# SF32LB58x register map
File version: 1.0
CPU: CM33 r0p1, little endian, MPU, FPU, 3 interrupt priority bits
Registers are 32-bit, read-write, reset 0x0 unless marked. A register's access mark holds for its fields unless they carry their own. Offsets are from the block's base; [hi:lo] are bit positions; {n}, {i} and the like mark numbered series.

## JPEG_DEC
Base 0x4008A000
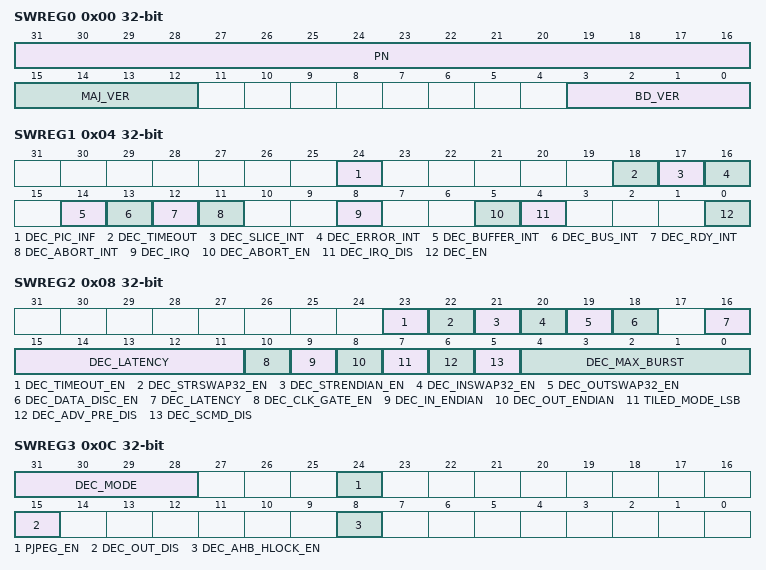
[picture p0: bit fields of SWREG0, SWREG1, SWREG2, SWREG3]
0x00 SWREG0
  [31:16] PN — Product number
  [15:12] MAJ_VER — Major version
  [3:0] BD_VER — Build version(core number)
0x04 SWREG1
  [24] DEC_PIC_INF — B slice detected. This signal is driven high during picture ready interrupt if B-type slice is found. This bit does not generate an interrupt but is used to inform SW about h264 tools. DIVX3: For DIVX3 this bit tells the value of extension header flag (flag called FLIPFLOP)
  [18] DEC_TIMEOUT — Interrupt status bit decoder timeout. When high the decoder has been idling for too long. HW will self reset. Possible only if timeout interrupt is enabled.
  [17] DEC_SLICE_INT — Interrupt status bit dec_slice_decoded . When high SW must set new base addresses for sw_dec_out_base and sw_jpg_ch_out_base before resetting this status bit. Used for JPEG and VP8 web-p modes.
  [16] DEC_ERROR_INT — Interrupt status bit input stream error . When high, an error is found in input data stream decoding. HW will self reset.
  [14] DEC_BUFFER_INT — Interrupt status bit input buffer empty. When high, input stream buffer is empty but picture is not ready. HW will not self reset.
  [13] DEC_BUS_INT — Interrupt status bit bus. Error response from bus.
  [12] DEC_RDY_INT — Interrupt status bit decoder. When this bit is high decoder has decoded a picture. HW will self reset.
  [11] DEC_ABORT_INT — Interrupt status bit decoding aborted. When this bit is high decoder has aborted the current picture decoding as SW requested (sw_dec_abort_e). Decoder self reset and sw_dec_abort_e written low.
  [8] DEC_IRQ — Decoder IRQ. When high, decoder requests an interrupt. SW will reset this after interrupt is handled.
  [5] DEC_ABORT_EN — Abort decoding enable. Setting this bit high will cause HW to abort decoding and safely to reset itself down. After abort is complete the corresponding interrupt status is set and this bit is set low as well as the decoder enable.
  [4] DEC_IRQ_DIS — Decoder IRQ disable. When high, there are no interrupts concerning decoder from HW. Polling must be used to see the interrupt statuses.
  [0] DEC_EN — Decoder enable. Setting this bit high will start the decoding operation. HW will reset this when picture is processed or ASO or stream error is detected or bus error or timeout interrupt is given.
0x08 SWREG2
  [23] DEC_TIMEOUT_EN — Timeout interrupt enable. If enabled HW may return timeout interrupt in case HW gets stucked while decoding picture.
  [22] DEC_STRSWAP32_EN — Decoder input 32bit data swap for stream data (may be used for 64 bit environment): ‘0’ = no swapping of 32 bit words ‘1’ = 32 bit data words are swapped (needed in 64 bit environment to achieve 7-6-5-4-3-2-1-0 byte order(also little endian should be enabled)
  [21] DEC_STRENDIAN_EN — Decoder input endian mode for stream data: 0 = Big endian (0-1-2-3 order) 1 = Little endian (3-2-1-0 order)
  [20] DEC_INSWAP32_EN — Decoder input 32 bit data swap for other than stream data (may be used for 64 bit environment): ‘0’ = no swapping of 32 bit words ‘1’ = 32 bit data words are swapped (needed in 64 bit environment to achieve 7-6-5-4-3-2-1-0 byte order(also little endian should be enabled).
  [19] DEC_OUTSWAP32_EN — Decoder output 32 bit data swap (may be used for 64 bit environment): ‘0’ = no swapping of 32 bit words ‘1’ = 32 bit data words are swapped (needed in 64 bit environment to achieve 7-6-5-4-3-2-1-0 byte order(also little endian should be enabled).
  [18] DEC_DATA_DISC_EN — Data discard enable. Precise burst lengths are used with reading services. Extra data is discarded internally. Note. If AHB maxburst 17 is used data discard cannot be enabled (causes conflict).
  [16:11] DEC_LATENCY
  [10] DEC_CLK_GATE_EN — Decoder dynamic clock gating enable: 0 = Clock is running for all structures 1 = Clock is gated for decoder structures that are not used Note: Clock gating value can be changed only when decoder is disabled
  [9] DEC_IN_ENDIAN — Decoder input endian mode for other than stream data: 0 = Big endian (0-1-2-3 order) 1 = Little endian (3-2-1-0 order)
  [8] DEC_OUT_ENDIAN — Decoder output endian mode: 0 = Big endian (0-1-2-3 order) 1 = Little endian (3-2-1-0 order)
  [7] TILED_MODE_LSB — Tiled mode LSB. Concatenated to Tiled mode MSB which form 2 bit tiled mode. Defined in tiled_mode_msb.
  [6] DEC_ADV_PRE_DIS — Advanced PREFETCH mode disable (advanced reference picture reading mode for video)
  [5] DEC_SCMD_DIS — AXI Single Command Multiple Data disable. AXI wrapper supports this mode by default (where only the first addresses of the burst are given from address generator). This bit is used to disable the feature (possible SW workaround if something is not working correctly).
  [4:0] DEC_MAX_BURST — Maximum burst length for decoder bus transactions. Valid values: AHB: 1, 4, 8, 16 and 17. Other values will result in INCR type (undefined length) for all transfers. INCR used for lengths 2 and 3. 17 = fixed bursts are used when possible. INCR bursts are used for lengths 2, 3, 5, 6, 7, 9, 10, 11, 12, 13, 14 and 15. OCP: 16-31 AXI: 1-16
0x0C SWREG3
  [31:28] DEC_MODE — Decoding mode: 0 = H.264, 1 = MPEG-4, 2 = H.263, 3 = JPEG, 4 = VC-1, 5 = MPEG-2, 6 = MPEG-1, 7 = VP6, 8 = RV, 9 = VP7, 10 = VP8, 11 = AVS, others = reserved
  [24] PJPEG_EN — Progressive JPEG enable: '0' = baseline JPEG '1' = progressive JPEG
  [15] DEC_OUT_DIS — Disable decoder output picture writing: 0 = Decoder output picture is written to external memory 1 = Decoder output picture is not written to external memory
  [8] DEC_AHB_HLOCK_EN — AHB master HLOCK enable. When high the service is locked to the decoder as long as it needs the bus (whenever decoder requests the bus it will be granted).
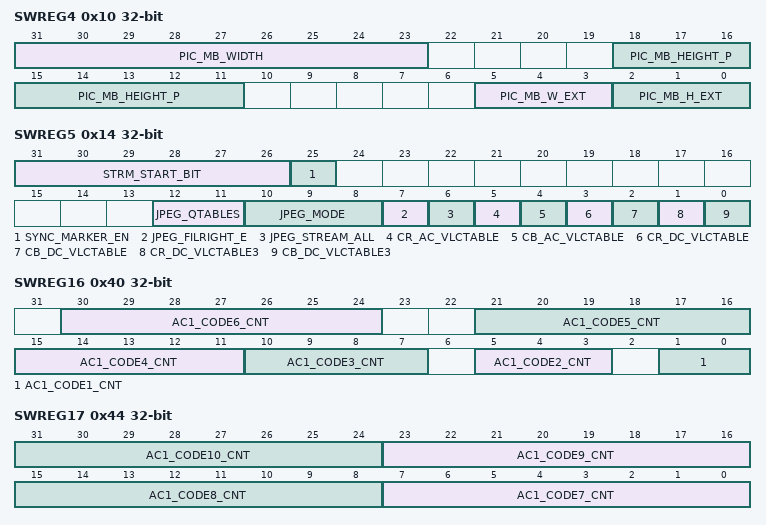
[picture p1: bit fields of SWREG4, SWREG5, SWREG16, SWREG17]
0x10 SWREG4
  [31:23] PIC_MB_WIDTH — Picture width in macroblocks = ((width in pixels + 15) /16)
  [18:11] PIC_MB_HEIGHT_P — Picture height in macroblocks =((height in pixels+15)/16). Picture height is informed as size of the (progressive) frame also for single field (of interlaced content) is being decoded.
  [5:3] PIC_MB_W_EXT — Picture MB width extension. If sw_pic_mb_width does not fit to 9 bits then these bits are used to increase the range up to 11 bits (used as 3 MSB).
  [2:0] PIC_MB_H_EXT — Picture MB height extension. If sw_pic_mb_height_p does not fit to 9 bits then these bits are used to increase the range up to 11 bits (used as 3 MSB). For 4K video, one bit is used for extension (bit 0).
0x14 SWREG5
  [31:26] STRM_START_BIT — Exact bit of stream start word where decoding can be started (associated with sw_rlc_vlc_base).
  [25] SYNC_MARKER_EN — Sync markers enable: '0' = synch markers are not used, '1' = synch markers are used. For progressive JPEG this indicates that there are restart markers in the stream after restart interval steps.
  [12:11] JPEG_QTABLES — Amount of Quantization tables in external memory: 0 = No quantization tables. (not supported) 1 = One quantization table. Used when picture is single type 2 = Two quantization tables. One for luminance and one for chominances. (not supported) 3 = Three quantization tables. Each type (Lu, Cr, Cb) has own QP-table Base address for tables is defined in swreg40.
  [10:8] JPEG_MODE — Input picture sampling format: 0 = single type, MB 1 block, 1 = single type, MB 4 blocks (not supported), 2 = three types, MB 6 blocks (4:2:0), 3 = three types, MB 4 blocks (4:2:2), 4 = three types, MB 3 blocks (4:4:4) 5 = three types, MB 4 blocks (4:4:0) 6 = three types, MB 6 blocks (4:1:1)
  [7] JPEG_FILRIGHT_E — 0 = JPEG picture width is a multiple of 16. 1 = JPEG picture width is a multiple of 8 pixels but not a multiple of 16 pixels. Can be set to 1 only for JPEG sampling format 0. HW must fill one block of zero pixel data to the right border of the picture.
  [6] JPEG_STREAM_ALL — 0 = Current stream buffer does not contain the end of a JPEG image. HW will not flush the stream data pipeline after a buffer empty request. 1 = Current stream buffer contains the end of a JPEG image. HW will flush data pipeline and will not request more stream providing it finds the EOI pattern at the end.
  [5] CR_AC_VLCTABLE — Defines which VLC table should be used for decoding AC components of the Cr. 0 = first, 1 = second. (For luminance the first table is always used)
  [4] CB_AC_VLCTABLE — Defines which VLC table should be used for decoding AC components of the Cb. 0 = first, 1 = second. (For luminance the first table is always used)
  [3] CR_DC_VLCTABLE — Defines which VLC table should be used for decoding DC components of the Cr. 0 = first/third depending on sw_cr_dc_vlctable3 position, 1 = second. (For luminance the first table is always used)
  [2] CB_DC_VLCTABLE — Defines which VLC table should be used for decoding DC components of the Cb. 0 = first/third depending on sw_cr_dc_vlctable3 position, 1 = second. (For luminance the first table is always used)
  [1] CR_DC_VLCTABLE3 — Progressive JPEG: Defines if third VLC table for DC components should be used for Cr. Note: sw_cr_dc_vlctable must be set to '0'
  [0] CB_DC_VLCTABLE3 — Progressive JPEG: Defines if third VLC table for DC components should be used for Cb. Note: sw_cb_dc_vlctable must be set to '0'
0x18 SWREG6
  [23:0] STREAM_LEN — Amount of stream data bytes in input buffer. If the given buffer size is not enough for finishing the picture the corresponding interrupt is given and new stream buffer base address and stream buffer size information should be given (associated with sw_rlc_vlc_base). For VC-1/VP6 the buffer must include data for one picture/slice of the picture. For H264/MPEG4/H263/MPEG2/MPEG1 the buffer must include at least data for one slice/VP of the picture For JPEG the buffer size must be a multiple of 256 bytes or the amount of data for one picture.
0x30 SWREG12
  [31:2] RLC_VLC_BASE — RLC mode: Base address for RLC data (swreg3.sw_rlc_mode_e = 1). VLC mode: Stream start address / end addr+I288ess with byte precision (swreg4.rlc_mode_en = 0), start bit number in swreg5.stream_start_bit. When sw_dec_buffer_int is high or sw_dec_e is low this register contains HW return value of last_byte_address (not valid for jpeg) where stream has been read (and used) in accuracy of byte. For debug purposes the last_byte_address is also written when stream error/ASO is detected even though it may not be accurate. VP7/VP8: This base address is used as sw_dct_strm0_base including DCT stream for MB rows 0,2n
0x34 SWREG13
  [31:2] DEC_OUT_BASE — Video: Base address for decoder output picture. Points directly to start of decoder output picture or field. JPEG/web-p: Base address for decoder output luminance picture
0x38 SWREG14
  [31:2] JPG_CH_OUT_BASE — Base address for decoder output chrominance picture. Used in JPEG and webP picture mode (not needed if decoder output is not written).
0x3C SWREG15
  [7:0] JPEG_SLICE_H — JPEG/Web-p. Height of the slice (multiple of 16 pixels) that HW decodes before interrupt. When slice is decoded HW will generate an interrupt and reset external addresses back to base address. Note, value 0 disables slice mode. Slice mode must be used if picture size is more than 16 Mpixels. However for bigger than 4096 MBs the slice mode usage is recommended.
0x40 SWREG16
  [30:24] AC1_CODE6_CNT — Amount of code words of length 6
  [21:16] AC1_CODE5_CNT — Amount of code words of length 5
  [15:11] AC1_CODE4_CNT — Amount of code words of length 4
  [10:7] AC1_CODE3_CNT — Amount of code words of length 3
  [5:3] AC1_CODE2_CNT — Amount of code words of length 2
  [1:0] AC1_CODE1_CNT — Amount of code words of length 1
0x44 SWREG17
  [8n-49:8n-56] AC1_CODE{n}_CNT (n=7..10) — Amount of code words of length {n}
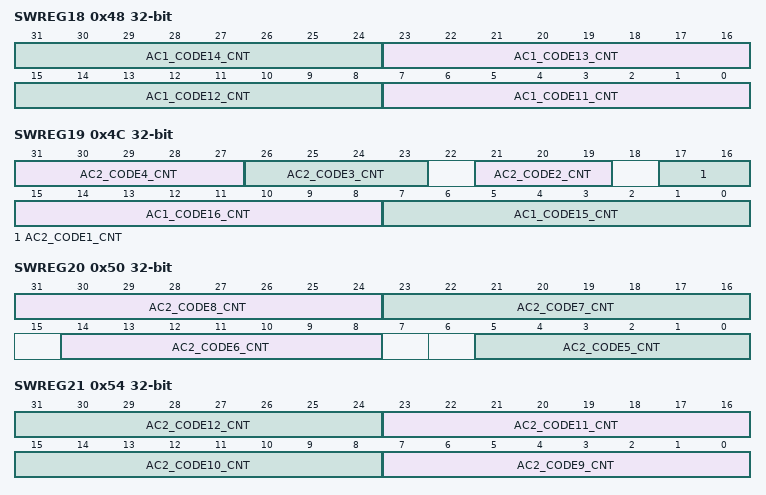
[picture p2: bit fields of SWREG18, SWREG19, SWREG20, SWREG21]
0x48 SWREG18
  [8n-81:8n-88] AC1_CODE{n}_CNT (n=11..14) — Amount of code words of length {n}
0x4C SWREG19
  [31:27] AC2_CODE4_CNT — Amount of code words of length 4 (second table)
  [26:23] AC2_CODE3_CNT — Amount of code words of length 3 (second table)
  [21:19] AC2_CODE2_CNT — Amount of code words of length 2 (second table)
  [17:16] AC2_CODE1_CNT — Amount of code words of length 1 (second table)
  [15:8] AC1_CODE16_CNT — Amount of code words of length 16 (first table)
  [7:0] AC1_CODE15_CNT — Amount of code words of length 15 (first table)
0x50 SWREG20
  [31:24] AC2_CODE8_CNT — Amount of code words of length 8
  [23:16] AC2_CODE7_CNT — Amount of code words of length 7
  [14:8] AC2_CODE6_CNT — Amount of code words of length 6
  [5:0] AC2_CODE5_CNT — Amount of code words of length 5
0x54 SWREG21
  [8n-65:8n-72] AC2_CODE{n}_CNT (n=9..12) — Amount of code words of length {n}
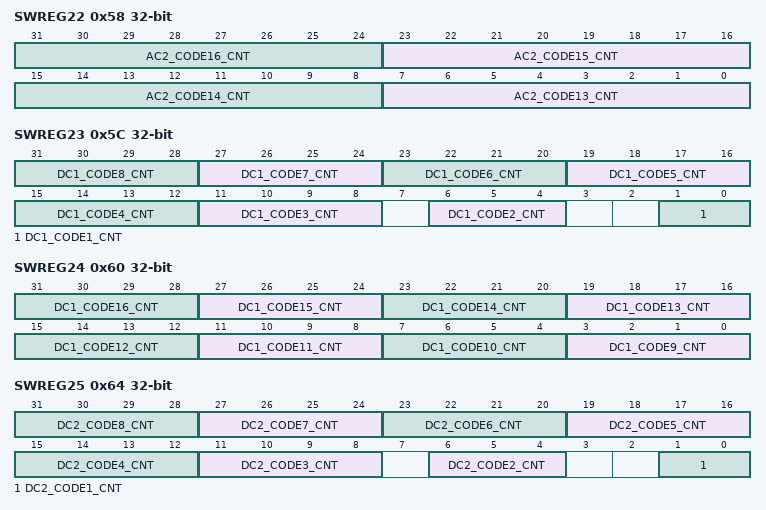
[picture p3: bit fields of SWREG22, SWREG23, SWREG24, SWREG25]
0x58 SWREG22
  [8n-97:8n-104] AC2_CODE{n}_CNT (n=13..16) — Amount of code words of length {n}
0x5C SWREG23
  [4n-1:4n-4] DC1_CODE{n}_CNT (n=3..8) — Amount of code words of length {n}
  [6:4] DC1_CODE2_CNT — Amount of code words of length 2
  [1:0] DC1_CODE1_CNT — Amount of code words of length 1
0x60 SWREG24
  [4n-33:4n-36] DC1_CODE{n}_CNT (n=9..16) — Amount of code words of length {n}
0x64 SWREG25
  [4n-1:4n-4] DC2_CODE{n}_CNT (n=3..8) — Amount of code words of length {n}
  [6:4] DC2_CODE2_CNT — Amount of code words of length 2
  [1:0] DC2_CODE1_CNT — Amount of code words of length 1
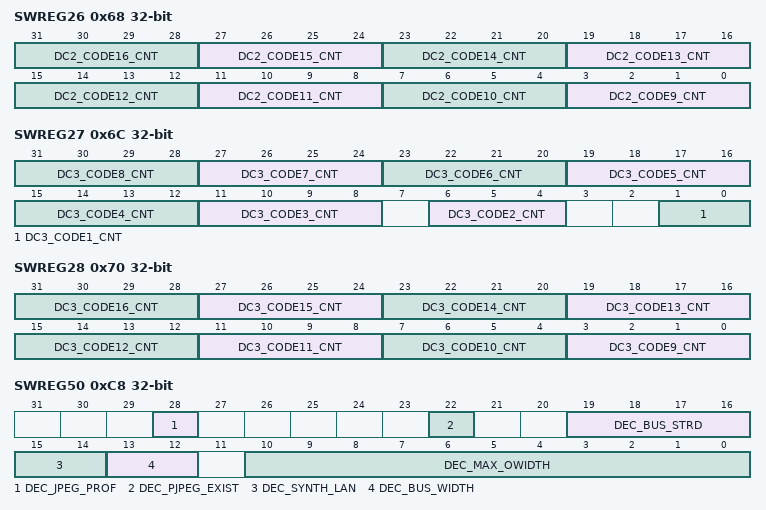
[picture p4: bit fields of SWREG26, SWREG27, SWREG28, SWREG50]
0x68 SWREG26
  [4n-33:4n-36] DC2_CODE{n}_CNT (n=9..16) — Amount of code words of length {n}
0x6C SWREG27
  [4n-1:4n-4] DC3_CODE{n}_CNT (n=3..8) — Amount of code words of length {n}
  [6:4] DC3_CODE2_CNT — Amount of code words of length 2
  [1:0] DC3_CODE1_CNT — Amount of code words of length 1
0x70 SWREG28
  [4n-33:4n-36] DC3_CODE{n}_CNT (n=9..16) — Amount of code words of length {n}
0xA0 SWREG40
  [31:2] QTABLE_BASE — Base address for standard dependent tables: JPEG= AC, DC, QP tables MPEG4=QP table base address if type 1 quantization is used MPEG2=QP table base address H.264=base address for various tables VP6,VP7,VP8=base address for stream decoding tables RV=base address for picture slice sizes
0xA4 SWREG41
  [31:2] DIR_MV_BASE — Direct mode motion vector write/read base address. For H264 this is used only for direct mode motion vector write base. Progressive JPEG: AC/DC coefficient read/write base address. If current round is for DC components this base address is pointing to luminance (separate base adderesses for chrominances), for AC component rounds this base is used for current type VP8: Motion vectors are written for error concealment purposes if sw_write_mvs is high. In error concealment mode motion vectors are read from this base address
0xC8 SWREG50
  [28] DEC_JPEG_PROF — Decoding format support, JPEG 0 = not supported 1 = supported
  [22] DEC_PJPEG_EXIST — Progressive JPEG support: '0' = Not supported '1' = supported
  [19:16] DEC_BUS_STRD — Connected to standard bus: 0 = error 1 = AHB master, AHB slave 2 = OCP master, OCP slave 3 = AXI master, AXI slave 4 = AXI master, APB slave 5 = AXI master, AHB slave
  [15:14] DEC_SYNTH_LAN — 0 = error 1 = VHDL 2 = Verilog
  [13:12] DEC_BUS_WIDTH — 0 = error 1 = 32 bit bus 2 = 64 bit bus 3 = 128 bit bus
  [10:0] DEC_MAX_OWIDTH — Max configured decoder video resolution that can be decoded. Informed as width of the picture in pixels.
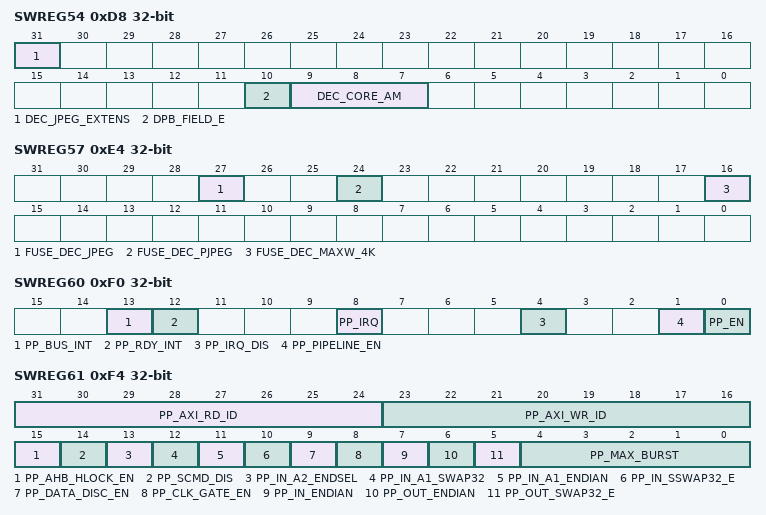
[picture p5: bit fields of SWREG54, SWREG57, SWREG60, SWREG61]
0xD8 SWREG54
  [31] DEC_JPEG_EXTENS — JPEG sampling support extension for 411 and 444 samplings and support for max resolution larger than 16 Mpix (up to 67 Mpixels): '0' = not supported '1' = supported
  [10] DPB_FIELD_E — DPB field separate mode support for ilaced content: '0' = Not supported (for ilaced content DPB is ilaced frame order) '1' = Supported, For ilaced content DPB can consis of ilaced frames or separate fields (TOP/BOT)
  [9:7] DEC_CORE_AM — Decoder core amount. If other than 0 the multicore can be used. Each individual cores can be identified from corresponding core ID register: 0= single core decoder 1= dual core decoder ... 7=8 core decoder
0xE4 SWREG57
  [27] FUSE_DEC_JPEG — 1 = JPEG enabled
  [24] FUSE_DEC_PJPEG — 1 = Progressive JPEG enabled (Requires JPEG to also be enabled)
  [16] FUSE_DEC_MAXW_4K — 1 = Max video width up to 4096 pixels enabled. Priority coded with priority 1.
0xE8 SWREG58
  [31] SERV_MERGE_DIS — Decoder service merge disable: '0': HW merges simultaneous sub-block requests internally if they are same type (read or write) '1': decoder serves one sub-block per service and merging is disabled.
0xF0 SWREG60
  [13] PP_BUS_INT — Interrupt status bit bus. Error response from bus. In pipeline mode this bit is not used.
  [12] PP_RDY_INT — Interrupt status bit post processor. When this bit is high, post processor has processed a picture in external mode. In pipeline mode this bit is not used.
  [8] PP_IRQ — Post-processor IRQ. SW will reset this after interrupt is handled. HINTpp is not used for PP if IRQ disable PP is high (sw_pp_irq_n_e = 1). In pipeline mode this bit is not used
  [4] PP_IRQ_DIS — Post-processor IRQ disabled. When high, there are no interrupts from HW concerning post processing. Polling must be used to see the interrupt
  [1] PP_PIPELINE_EN — Decoder – post-processing pipeline enable: 0 = Post-processing is processing different picture than decoder or is disabled 1 = Post-processing is performed in pipeline with decoder
  [0] PP_EN — External mode post-processing enable. This bit will start the post-processing operation. Not to be used if PP is in pipeline with decoder (sw_pp_pipeline_e = 1). HW will reset this when picture is post-processed.
0xF4 SWREG61
  [31:24] PP_AXI_RD_ID — Read ID used for AXI PP read services (if connected to AXI). If value 255 is given the decoder will provide data type based dynamic index (defined in toplevel_sp).
  [23:16] PP_AXI_WR_ID — Write ID used for AXI PP write services (if connected to AXI). If value 255 is given the decoder will provide data type based dynamic index (defined in toplevel_sp).
  [15] PP_AHB_HLOCK_EN — AHB master HLOCK enable. When high the service is locked to PP as long as it needs the bus (whenever PP requests the bus it will be granted).
  [14] PP_SCMD_DIS — AXI Single Command Multiple Data disable. AXI wrapper supports this mode by default (where only the first addresses of the burst are given from address generator). This bit is used to disable the feature (possible SW workaround if something is not working correctly).
  [13] PP_IN_A2_ENDSEL — Endian/swap select for Alpha blend input source 2: '0' = Use PP in endian/swap definitions (sw_pp_in_endian, sw_pp_in_swap ) '1' = Use Alpha blend source 1 endian/swap definitions (sw_pp_in_a1_endian, sw_pp_in_a1_swap )
  [12] PP_IN_A1_SWAP32 — Alpha blend source 1 input 32 bit data swap (may be used for 64 bit environment): ‘0’ = no swapping of 32 bit words ‘1’ = 32 bit data words are swapped (needed in 64 bit environment to achieve 7-6-5-4-3-2-1-0 byte order (also little endian should be enabled)
  [11] PP_IN_A1_ENDIAN — Alpha blend source 1 input data byte endian mode. 0 = Big endian (0-1-2-3 order) 1 = Little endian (3-2-1-0 order)
  [10] PP_IN_SSWAP32_E — PP input 32 bit data swap (may be used for 64 bit environment): ‘0’ = no swapping of 32 bit words ‘1’ = 32 bit data words are swapped (needed in 64 bit environment to achieve 7-6-5-4-3-2-1-0 byte order (also little endian should be enabled).
  [9] PP_DATA_DISC_EN — PP data discard enable. Precise burst lengths are used with reading services. Extra data is discarded internally. Note. If AHB maxburst 17 is used data discard cannot be enabled (causes conflict).
  [8] PP_CLK_GATE_EN — PP dynamic clock gating enable: 1 = Clock is gated from PP structures that are not used 0 = Clock is running for all PP structures Note: Clock gating value can be changed only when PP is not enabled
  [7] PP_IN_ENDIAN — PP input picture byte endian mode. Used only if PP is in standalone mode. If PP is running pipelined with the decoder, this bit has no effect. 0 = Big endian (0-1-2-3 order) 1 = Little endian (3-2-1-0 order)
  [6] PP_OUT_ENDIAN — PP output picture endian mode for YCbCr data or for any data if config value SW_PP_OEN_VERSION=1 0 = Big endian (0-1-2-3 order) 1 = Little endian (3-2-1-0 order) (NOTE: For SW_PP_OEN_VERSION=0 16 bit RGB data this bit works as pixel swapping bit. For 32 bit RGB this bit has no meaning)
  [5] PP_OUT_SWAP32_E — PP output data word swap (may be used for 64 bit environment): ‘0’ = no swapping of 32 bit words ‘1’ = 32 bit data words are swapped (needed in 64 bit environment to achieve 7-6-5-4-3-2-1-0 byte order (also little endian should be enabled).
  [4:0] PP_MAX_BURST — Maximum burst length for PP bus transactions. Valid values: AHB: 1, 4, 8 , 16 and 17. Other values will result in INCR type (undefined length) transfers 17 = fixed bursts are used when possible. INCR bursts for others OCP: 16-31 AXI: 1-16
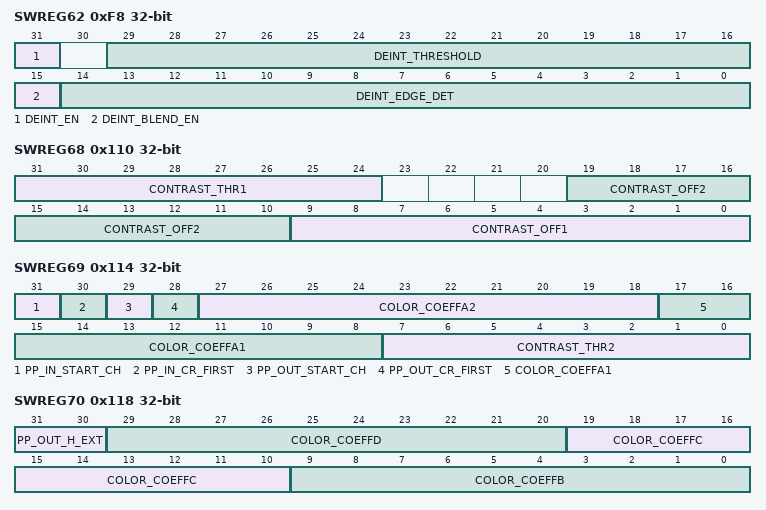
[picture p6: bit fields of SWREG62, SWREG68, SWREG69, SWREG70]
0xF8 SWREG62
  [31] DEINT_EN — De-interlace enable. Input data is in interlaced format and deinterlacing needs to be performed
  [29:16] DEINT_THRESHOLD — Threshold value used in deinterlacing
  [15] DEINT_BLEND_EN — Blend enable for de-interlacing
  [14:0] DEINT_EDGE_DET — Edge detect value used for deinterlacing
0xFC SWREG63
  [31:2] PP_IN_LU_BASE — Base address for post-processing input luminance picture. If PP input picture is fetched from fields this base address is used to point to top field of the picture. Used in external mode only.
0x100 SWREG64
  [31:2] PP_IN_CB_BASE — Base address for post-processing input Cb picture or for both chrominance pictures (if chrominances interleaved). If PP input picture is fetched from fields this base address is used to point to top field of the picture. Used in external mode only.
0x104 SWREG65
  [31:2] PP_IN_CR_BASE — Base address for post-processing input Cr picture. Used in external mode only.
0x108 SWREG66
  [31:2] PP_OUT_LU_BASE — Base address for post-processing output picture (luminance/YUYV/RGB). NOTE: Bits 2:0 are used to adjust the post-processor output to start from zertain byte (1:0 for 32 bit bus). These bits can be other than zero only if Pixel Accurate PP output configuration is enabled.
0x10C SWREG67
  [31:0] PP_OUT_CH_BASE — Base address for post-processing output chrominance picture (interleaved chrominance). NOTE: Bits 2:0 are used to adjust the post-processor output to start from a certain byte (1:0 for 32 bit bus). These bits can be other than zero only if Pixel Accurate PP output configuration is enabled.
0x110 SWREG68
  [31:24] CONTRAST_THR1 — Threshold value 1, used with contrast adjusting
  [19:10] CONTRAST_OFF2 — Offset value 2, used with contrast adjusting
  [9:0] CONTRAST_OFF1 — Offset value 1, used with contrast adjusting
0x114 SWREG69
  [31] PP_IN_START_CH — For YUYV 422 input format. Enable for start_with_chrominance. '0' =the order is Y0CbY0Cr or Y0CrY0Cb '1'= the order is CbY0CrY0 or CrY0CbY0
  [30] PP_IN_CR_FIRST — For YUYV 422 input format. Enable for Cr first (before Cb) '0' =the order is Y0CbY0Cr or CbY0CrY0 (if 420 semiplanar chrominance: CbCrCbCr) '1'= the order is Y0CrY0Cb or CrY0CbY0 (if 420 semiplanar chrominance: CrCbCrCb)
  [29] PP_OUT_START_CH — For YUYV 422 output format. Enable for start_with_chrominance. '0' =the order is Y0CbY0Cr or Y0CrY0Cb '1'= the order is CbY0CrY0 or CrY0CbY0
  [28] PP_OUT_CR_FIRST — For YUYV 422 output format. Enable for Cr first (before Cb) '0' =the order is Y0CbY0Cr or CbY0CrY0 '1'= the order is Y0CrY0Cb or CrY0CbY0
  [27:18] COLOR_COEFFA2 — Coefficient a2, used with Y pixel to calculate all color components
  [17:8] COLOR_COEFFA1 — Coefficient a1, used with Y pixel to calculate all color components
  [7:0] CONTRAST_THR2 — Threshold value 2, used with contrast adjusting
0x118 SWREG70
  [31:30] PP_OUT_H_EXT — Extended output height for 4k resolution
  [29:20] COLOR_COEFFD — Coefficient d, used with Cb to calculate green component value
  [19:10] COLOR_COEFFC — Coefficient c, used with Cr to calculate green component value
  [9:0] COLOR_COEFFB — Coefficient b, used with Cr to calculate red component value
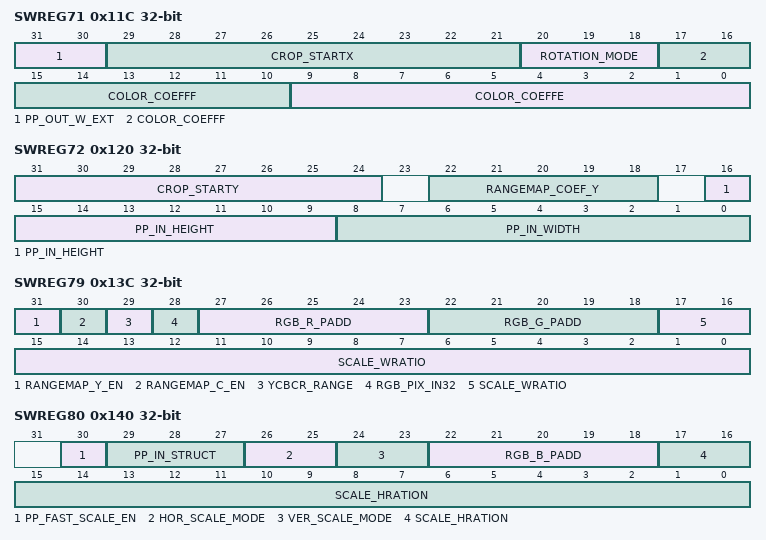
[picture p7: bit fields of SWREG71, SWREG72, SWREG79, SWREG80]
0x11C SWREG71
  [31:30] PP_OUT_W_EXT — Extended output width for 4k resolution
  [29:21] CROP_STARTX — Start coordinate x for the cropped area in macroblocks.
  [20:18] ROTATION_MODE — Rotation mode: “000” = rotation disabled “001” = rotate + 90° “010” = rotate – 90° “011” = horizontal flip (mirror) “100” = vertical flip "101" = rotate 180°
  [17:10] COLOR_COEFFF — Coefficient f, used with Y to adjust brightness
  [9:0] COLOR_COEFFE — Coefficient e, used with Cb to calculate blue component value
0x120 SWREG72
  [31:24] CROP_STARTY — Start coordinate y for the cropped area in macroblocks.
  [22:18] RANGEMAP_COEF_Y — Range map value for Y component (RANGE_MAPY+9 in VC-1 standard)
  [16:9] PP_IN_HEIGHT — PP input picture height in MBs. Can be cropped from a bigger input picture in external mode.
  [8:0] PP_IN_WIDTH — PP input picture width in MBs. Can be cropped from a bigger input picture in external mode.
0x124 SWREG73
  [31:2] PP_BOT_YIN_BASE — PP input Y base for bottom field
0x128 SWREG74
  [31:2] PP_BOT_CIN_BASE — PP input C base for bottom field (mixed chrominance)
0x13C SWREG79
  [31] RANGEMAP_Y_EN — Range map enable for Y component (RANGE_MAPY_FLAG in VC-1 standard). For VC1 main profile this bit is used as range expansion enable.
  [30] RANGEMAP_C_EN — Range map enable for chrominance component (RANGE_MAPUV_FLAG in VC-1 standard)
  [29] YCBCR_RANGE — Defines the YCbCr range in RGB conversion: ‘0’ = 16…235 for Y, 16…240 for Chrominance ‘1’ = 0…255 for all components
  [28] RGB_PIX_IN32 — RGB pixel amount/ 32 bit word ‘0’ = 1 RGB pixel/32 bit ‘1’ = 2 RGB pixels/32 bit
  [27:23] RGB_R_PADD — Amount of ones that will be padded in front of the R-component.
  [22:18] RGB_G_PADD — Amount of ones that will be padded in front of the G-component.
  [17:0] SCALE_WRATIO — Scaling ratio for width (outputw-1/inputw-1)
0x140 SWREG80
  [30] PP_FAST_SCALE_EN — 0' = fast downscaling is not enabled '1' = fast downscaling is enabled. The quality of the picture is decreased but performance is improved.
  [29:27] PP_IN_STRUCT — PP input data picture structure: 0 = Top field / progressive frame structure: Read input data from top field base address /frame base address and read every line 1 = Bottom field structure: Read input data from bottom field base address and read every line. 2 = Interlaced field structure: Read input data from both top and bottom field base address and take every line from each field. 3 = Interlaced frame structure: Read input data from both top and bottom field base address and take every second line from each field. 4 = Ripped top field structure: Read input data from top field base address and read every second line. 5 = Ripped bottom field structure: Read input data from bottom field base address and read every second line
  [26:25] HOR_SCALE_MODE — Horizontal scaling mode: “00” = Off “01” = Upscale “10” = Downscale
  [24:23] VER_SCALE_MODE — Vertical scaling mode: “00” = Off “01” = Upscale “10” = Downscale
  [22:18] RGB_B_PADD — Amount of ones that will be padded in front of the B-component
  [17:0] SCALE_HRATION — Scaling ratio for height (outputh-1/inputh-1)
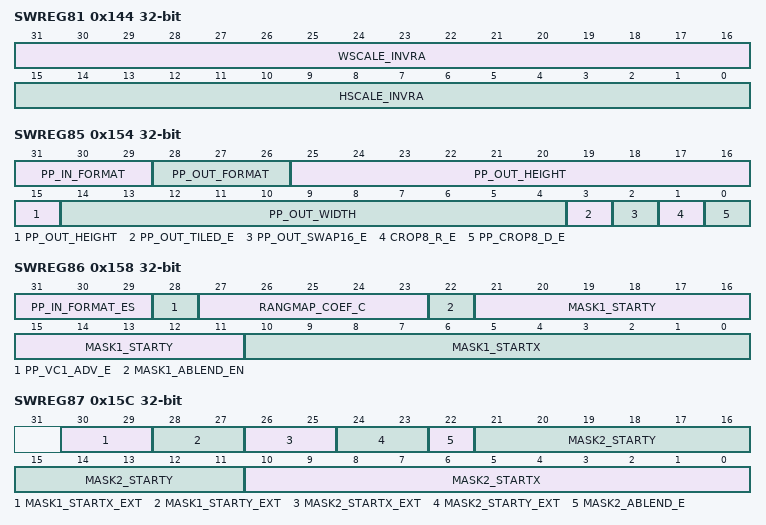
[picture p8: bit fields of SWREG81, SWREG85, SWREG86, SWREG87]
0x144 SWREG81
  [31:16] WSCALE_INVRA — Inverse scaling ratio for width, or ch (inputw-1 / outputw-1)
  [15:0] HSCALE_INVRA — Inverse scaling ratio for height or cv (inputh-1 / outputh-1)
0x148 SWREG82
  [31:0] R_MASK — Bit mask for R component (and alpha channel)
0x14C SWREG83
  [31:0] G_MASK — Bit mask for G component (and alpha channel)
0x150 SWREG84
  [31:0] B_MASK — Bit mask for B component (and alpha channel)
0x154 SWREG85
  [31:29] PP_IN_FORMAT — PP input picture data format 0 = YUYV 4:2:2 interleaved (supported only in external mode) 1 = YCbCr 4:2:0 Semi-planar in linear raster-scan format 2 = YCbCr 4:2:0 planar (supported only in external mode) 3 = YCbCr 4:0:0 (supported only in pipelined mode) 4 = YCbCr 4:2:2 Semi-planar (supported only in pipelined mode) 5 = YCbCr 4:2:0 Semi-planar in tiled format (supported only in external mode) 6 = YCbCr 4:4:0 Semi-planar (supported only in pipelined mode, possible for JPEG only) 7 = Escape PP input data format. Defined in swreg86
  [28:26] PP_OUT_FORMAT — PP output picture data format: 0 = RGB 1 = YCbCr 4:2:0 planar (Not supported) 2 = YCbCr 4:2:2 planar (Not supported) 3 = YUYV 4:2:2 interleaved 4 = YCbCr 4:4:4 planar (Not supported) 5 = YCh 4:2:0 chrominance interleaved 6 = YCh 4:2:2 (Not supported) 7 = YCh 4:4:4 (Not supported)
  [25:15] PP_OUT_HEIGHT — Scaled picture height in pixels (Must be divisable by 2 or by any if Pixel Accurate PP output configuration is enabled) Max scaled picture height is 1920 pixels or maximum three times the input source height minus 8 pixels
  [14:4] PP_OUT_WIDTH — Scaled picture width in pixels. Must be divisable by 8 or by any if Pixel Accurate PP output configuration is enabled. Max scaled picture width is 1920 pixels or maximum three times the input source width minus 8 pixels
  [3] PP_OUT_TILED_E — Tiled mode enable for PP output. Can be used only for YCbYCr 422 output format. Can be used only if correpongind configuration supports this feature. Tile size is 4x4 pixels.
  [2] PP_OUT_SWAP16_E — PP output swap 16 swaps 16 bit halfs inside of 32 bit word. Can be used for 16 bit RGB to change pixel orders but is valid also for any output format NOTE: requires that configuration of SW_PPD_OEN_VERSION=1
  [1] CROP8_R_E — PP input picture width is not 16 pixels multiple. Only 8 pixels of the most right MB of the unrotated input picture is used for PP input.
  [0] PP_CROP8_D_E — PP input picture height is not 16 pixels multiple. Only 8 pixel rows of the most down MB of the unrotated input picture is used for PP input.
0x158 SWREG86
  [31:29] PP_IN_FORMAT_ES — Escape PP in format. Used if sw_pp_in_format is defined to 7: 0 = YCbCr 4:4:4 1 = YCbCr 4:1:1
  [28] PP_VC1_ADV_E — PP requires this flag for range map control. '0' = Source is other than VC1 advanced profile '1' = input data source is from VC1 advanced profile
  [27:23] RANGMAP_COEF_C — Range map value for chrominance component (RANGE_MAPUV+9 in VC-1 standard)
  [22] MASK1_ABLEND_EN — Mask 1 alpha blending enable. Instead of masking the output picture the alpha blending is performed. Alpha blending source can be found from alpha blend 1 base address. Alpha blending can be enabled only for RGB/ YUYV 422 data.
  [21:11] MASK1_STARTY — Vertical start pixel for mask area 1. Defines the y coordinate. Coordinate 0,0 means the up-left corner in PP output luminance picture. See Table 47 for restrictions.
  [10:0] MASK1_STARTX — Horizontal start pixel for mask area 1. Defines the x coordinate. Coordinate 0,0 means the up-left corner in PP output luminance picture. See Table 47 for restrictions.
0x15C SWREG87
  [30:29] MASK1_STARTX_EXT — Extended coordinate up to 4k resolution
  [28:27] MASK1_STARTY_EXT — Extended coordinate up to 4k resolution
  [26:25] MASK2_STARTX_EXT — Extended coordinate up to 4k resolution
  [24:23] MASK2_STARTY_EXT — Extended coordinate up to 4k resolution
  [22] MASK2_ABLEND_E — Mask 2 alpha blending enable. Instead of masking the output picture the alpha blending is performed. Alpha blending source can be found from alpha blend 2 base address. Alpha blending can be enabled only for RGB/YUYV 422 data.
  [21:11] MASK2_STARTY — Verical start pixel for mask area 2. Defines the y coordinate. Coordinate (0, 0) means the upper-left corner in PP ouput Y picture. See Table 47 for restrictions.
  [10:0] MASK2_STARTX — Horizontal start pixel for mask area 2. Defines the x coordinate. Coordinate (0, 0) means the upper-left corner in PP output Y picture. See Table 47 for restrictions.
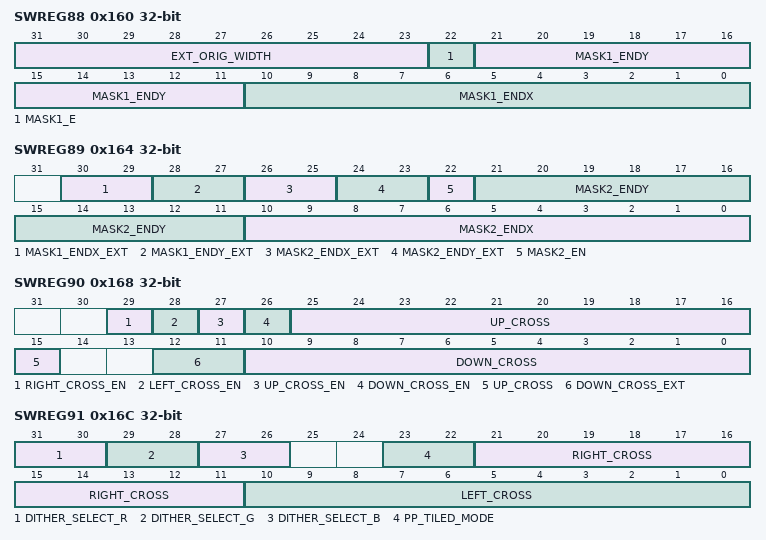
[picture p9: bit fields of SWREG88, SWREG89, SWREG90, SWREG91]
0x160 SWREG88
  [31:23] EXT_ORIG_WIDTH — PP input picture original width in macro blocks.
  [22] MASK1_E — Mask 1 enable. If mask 1 is used this bit is high.
  [21:11] MASK1_ENDY — Mask 1 end coordinate y in pixels (inside of PPD output picture). Range must be between [Mask1StartCoordinateY, ScaledHeight].
  [10:0] MASK1_ENDX — Mask 1 end coordinate x in pixels (inside of PPD output picture). Range must be between [Mask1StartCoordinateX, ScaledWidth].
0x164 SWREG89
  [30:29] MASK1_ENDX_EXT — Extended coordinate up to 4k resolution
  [28:27] MASK1_ENDY_EXT — Extended coordinate up to 4k resolution
  [26:25] MASK2_ENDX_EXT — Extended coordinate up to 4k resolution
  [24:23] MASK2_ENDY_EXT — Extended coordinate up to 4k resolution
  [22] MASK2_EN — Mask 2 enable. If mask 1 is used this bit is high.
  [21:11] MASK2_ENDY — Mask 2 end coordinate y in pixels (inside of PP output picture). Range must be between [Mask2StartCoordinateY, ScaledHeight].
  [10:0] MASK2_ENDX — Mask 2 end coordinate x in pixels (inside of PP output picture). Range must be between [Mask2StartCoordinateX, ScaledWidth].
0x168 SWREG90
  [29] RIGHT_CROSS_EN — Right side overcross enable. 0 = No right side overcross, 1 = right side overcross
  [28] LEFT_CROSS_EN — Left side overcross enable. 0 = No left side overcross, 1 = left side overcross
  [27] UP_CROSS_EN — Upward overcross enable. 0 = No upward overcross, 1 = upward overcross
  [26] DOWN_CROSS_EN — Downward overcross enable. 0 = No downward overcross, 1 = downward overcross
  [25:15] UP_CROSS — Amount of upward overcross (vertical pixels outside of display from the upper side). Range must be between [0, ScaledHeight].
  [12:11] DOWN_CROSS_EXT — Extended coordinate for 4k resolution
  [10:0] DOWN_CROSS — Amount of downward overcross (vertical pixels outside of displayfrom the down side). Range must be between [0, ScaledHeight].
0x16C SWREG91
  [31:30] DITHER_SELECT_R — Dithering control for R channel: "00" = dithering disabled "01" = use four-bit dither matrix "10" = use five-bit dither matrix "11" = use six-bit dither matrix
  [29:28] DITHER_SELECT_G — Dithering control for G channel: "00" = dithering disabled "01" = use four-bit dither matrix "10" = use five-bit dither matrix "11" = use six-bit dither matrix
  [27:26] DITHER_SELECT_B — Dithering control for B channel: "00" = dithering disabled "01" = use four-bit dither matrix "10" = use five-bit dither matrix "11" = use six-bit dither matrix
  [23:22] PP_TILED_MODE — Input data is in tiled mode (currently valid only for YCbCr 420 data, pipeline or external mode): 0 = Tiled mode not used 1 = Tiled mode enabled for 8x4 sized tiles 2,3 = reserved
  [21:11] RIGHT_CROSS — Amount of right side overcross (Horizontal pixels outside of display from the right side). Range must be between [0, ScaledWidth].
  [10:0] LEFT_CROSS — Amount of left side overcross (Horizontal pixels outside of display from the left side). Range must be between [0, ScaledWidth].
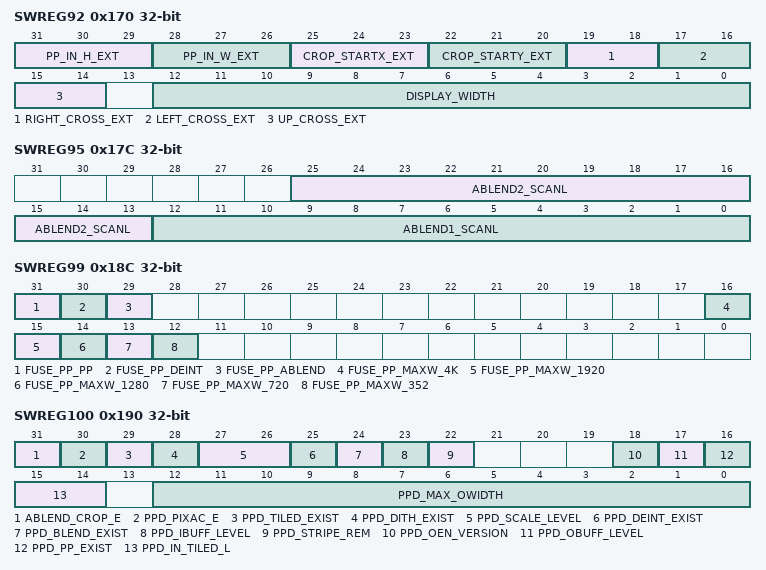
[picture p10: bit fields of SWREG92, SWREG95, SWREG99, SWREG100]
0x170 SWREG92
  [31:29] PP_IN_H_EXT — Extended PP input height. Used with JPEG/WEBP
  [28:26] PP_IN_W_EXT — Extended PP input width. Used with JPEG/WEBP
  [25:23] CROP_STARTX_EXT — Extended PP input crop start coordinate x. Used with JPEG/WebP
  [22:20] CROP_STARTY_EXT — Extended PP input crop start coordinate y. Used with JPEG/WebP
  [19:18] RIGHT_CROSS_EXT — Extended coordinate for 4k resolution
  [17:16] LEFT_CROSS_EXT — Extended coordinate for 4k resolution
  [15:14] UP_CROSS_EXT — Extended coordinate for 4k resolution
  [12:0] DISPLAY_WIDTH — Width of the display in pixels. Max 4k (depends on HW config support)
0x174 SWREG93
  [31:0] ABLEND1_BASE — Base address for alpha blending input 1 (if mask1 is used in alpha blending mode). Format of data is 24 bit RGB/ YCbCr and endian/swap -mode is as in PP input. Amount of data is informed with mask 1 size or with ablend1_scanline if alpha blend cropping is supported in configuration.
0x178 SWREG94
  [31:0] ABLEND2_BASE — Base address for alpha blending input 2 (if mask2 is used in alpha blending mode). Format of data is 24 bit RGB/ YCbCr and endian/swap -mode is as in PP input. Amount of data is informed with mask 2 size or with ablend2_scanline if alpha blend cropping is supported in configuration.
0x17C SWREG95
  [25:13] ABLEND2_SCANL — Scanline width in pixels for Alpha blend 2. Usage enabled if corresponding configuration bit is enabled.
  [12:0] ABLEND1_SCANL — Scanline width in pixels for Alpha blend 1. Usage enabled if corresponding configuration bit is enabled.
0x18C SWREG99
  [31] FUSE_PP_PP — 1 = PP enabled
  [30] FUSE_PP_DEINT — 1 = Deinterlacing enabled
  [29] FUSE_PP_ABLEND — 1 = Alpha Blending enabled
  [16] FUSE_PP_MAXW_4K — 1 = Max PP output width up to 4096 pixels enabled. Priority coded with priority 1
  [15] FUSE_PP_MAXW_1920 — 1 = Max PP output width up to 1920 pixels enabled. Priority coded with priority 2
  [14] FUSE_PP_MAXW_1280 — 1 = Max PP output width up to 1280 pixels enabled. Priority coded with priority 3
  [13] FUSE_PP_MAXW_720 — 1 = Max PP output width up to 720 pixels enabled. Priority coded with priority 4
  [12] FUSE_PP_MAXW_352 — 1 = Max PP output width up to 352 pixels enabled. Priority coded with priority 5
0x190 SWREG100
  [31] ABLEND_CROP_E — Alpha blending support for input cropping: '0': Not supported. External memory must include the exact image of the area being alpha blended '1': Supported. External memory can include a picture from blended area can be cropped. Requires usage of swreg95
  [30] PPD_PIXAC_E — Pixel Accurate PP output mode exists: '0' = PIP, Scaling and masks can be adjusted by steps of 8 pixels (width) or 2 pixels (height) '1' = PIP, Scaling and masks can be adjusted by steps of 1 pixel for RGB and 2 pixels for subsampled chroma formats (by using bus specific write strobe functionality)
  [29] PPD_TILED_EXIST — PP output YCbYCr 422 tiled support (4x4 pixel tiles) '0' = Not supported '1' = Supported
  [28] PPD_DITH_EXIST — Dithering exists: '0' = no '1' = yes
  [27:26] PPD_SCALE_LEVEL — Scaling support: "00" = No scaling "01" = Scaling with lo perfomance architecture "10" = Scaling with high performance architecture "11" = Scaling with high performance architecture + fast downscaling enabled
  [25] PPD_DEINT_EXIST — De-interlacing exits: '0' = no '1' = yes
  [24] PPD_BLEND_EXIST — Alpha blending exists: '0' = no '1' = yes
  [23] PPD_IBUFF_LEVEL — PP input buffering level: '0' = 1 MB input buffering is used '1' = 4 MB input buffering is used
  [22] PPD_STRIPE_REM — PP downscaling stripe removal: '0' = No removal '1' = Stripe removal used
  [18] PPD_OEN_VERSION — PP output endian version: '0' = Endian mode supported for other than RGB '1' = Endian mode supported for any output format
  [17] PPD_OBUFF_LEVEL — PP output buffering level: '0' = 1 unit output buffering is used '1' = 4 unit output buffering is used
  [16] PPD_PP_EXIST — PPD exists: '0'=no '1'=yes
  [15:14] PPD_IN_TILED_L — PPD input tiled mode support level 0 = not supported 1 = 8x4 tile size supported
  [12:0] PPD_MAX_OWIDTH — Max supported PP output width in pixels
